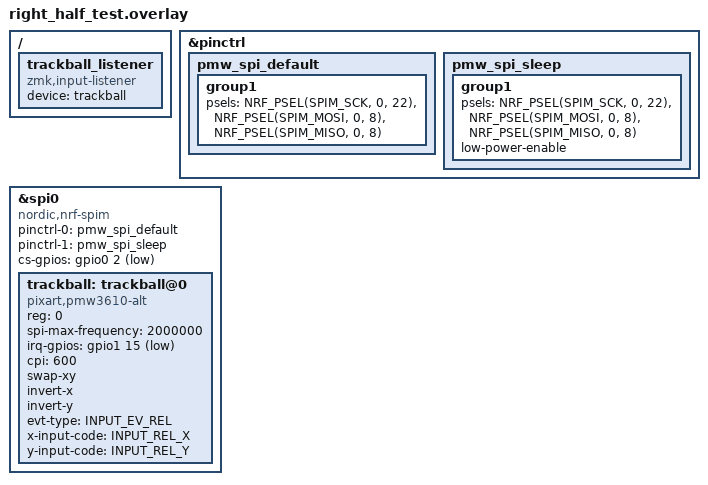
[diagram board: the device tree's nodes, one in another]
#include "right_half_test.dtsi"


#include <zephyr/dt-bindings/gpio/gpio.h>
#include <zephyr/dt-bindings/input/input-event-codes.h>
#include <zephyr/dt-bindings/pinctrl/nrf-pinctrl.h>

&pinctrl {
    pmw_spi_default: pmw_spi_default {
        group1 {
            psels = <NRF_PSEL(SPIM_SCK, 0, 22)>,
                    <NRF_PSEL(SPIM_MOSI, 0, 8)>,
                    <NRF_PSEL(SPIM_MISO, 0, 8)>;
        };
    };

    pmw_spi_sleep: pmw_spi_sleep {
        group1 {
            psels = <NRF_PSEL(SPIM_SCK, 0, 22)>,
                    <NRF_PSEL(SPIM_MOSI, 0, 8)>,
                    <NRF_PSEL(SPIM_MISO, 0, 8)>;
            low-power-enable;
        };
    };
};

&spi0 {
    status = "okay";
    compatible = "nordic,nrf-spim";
    pinctrl-0 = <&pmw_spi_default>;
    pinctrl-1 = <&pmw_spi_sleep>;
    pinctrl-names = "default", "sleep";
    cs-gpios = <&gpio0 2 GPIO_ACTIVE_LOW>;

 
trackball: trackball@0 {
    compatible = "pixart,pmw3610-alt";
    reg = <0>;
    spi-max-frequency = <2000000>;
    irq-gpios = <&gpio1 15 (GPIO_ACTIVE_LOW | GPIO_PULL_UP)>;
    cpi = <600>;

    swap-xy;
    invert-x;
    invert-y;

    evt-type = <INPUT_EV_REL>;
    x-input-code = <INPUT_REL_X>;
    y-input-code = <INPUT_REL_Y>;
    status = "okay";
};

};

/ {
    trackball_listener {
        compatible = "zmk,input-listener";
        device = <&trackball>;
    };
};
